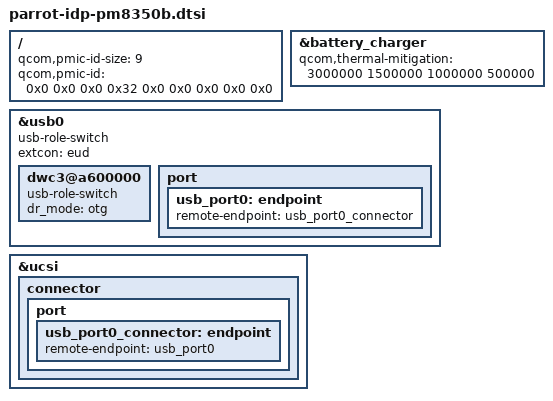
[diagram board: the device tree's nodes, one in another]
#include "parrot-pm8350b.dtsi"

/ {
	qcom,pmic-id-size = <9>;
	qcom,pmic-id = <0x0 0x0 0x0 0x32 0x0 0x0 0x0 0x0 0x0>;
};

&battery_charger {
	qcom,thermal-mitigation = <3000000 1500000 1000000 500000>;
};

&usb0 {
	usb-role-switch;
	extcon = <&eud>;

	dwc3@a600000 {
		usb-role-switch;
		dr_mode = "otg";
	};

	port {
		usb_port0: endpoint {
			remote-endpoint = <&usb_port0_connector>;
		};
	};
};

&ucsi {
	connector {
		port {
			usb_port0_connector: endpoint {
				remote-endpoint = <&usb_port0>;
			};
		};
	};
};
